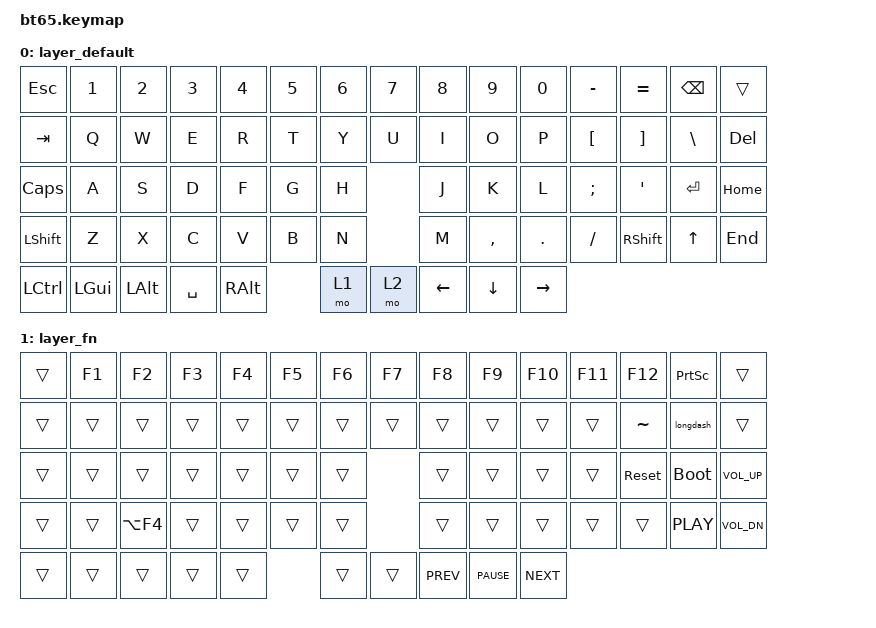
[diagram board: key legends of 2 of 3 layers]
#include <behaviors.dtsi>
#include <dt-bindings/zmk/keys.h>
#include <dt-bindings/zmk/bt.h>
#include <dt-bindings/zmk/rgb.h>
#include <dt-bindings/zmk/backlight.h>
#include <dt-bindings/zmk/ext_power.h>

/ {
    macros {
        longdash: longdash {
            label = "ZM_longdash";
            compatible = "zmk,behavior-macro";
            #binding-cells = <0>;
            bindings
                = <&macro_press &kp LALT>
                , <&macro_tap &kp KP_N0 &kp KP_N1 &kp KP_N5 &kp KP_N0>
                , <&macro_release &kp LALT>
                ;
        };
    };
};

/ {
	keymap {
		compatible = "zmk,keymap";

		layer_default {
			bindings = <

				&kp ESC &kp N1 &kp N2 &kp N3 &kp N4 &kp N5 &kp N6 &kp N7 &kp N8 &kp N9 &kp N0 &kp MINUS &kp EQUAL &kp BKSP &trans
				&kp TAB &kp Q &kp W &kp E &kp R &kp T &kp Y &kp U &kp I &kp O &kp P &kp LBKT &kp RBKT &kp BACKSLASH &kp DEL
				&kp CLCK &kp A &kp S &kp D &kp F &kp G &kp H &kp J &kp K &kp L &kp SEMI &kp SQT &kp RET &kp HOME
				&kp LSHFT &kp Z &kp X &kp C &kp V &kp B &kp N &kp M &kp COMMA &kp DOT &kp FSLH &kp RSHFT &kp UP &kp END
				&kp LCTRL &kp LGUI &kp LALT &kp SPACE &kp RALT &mo 1 &mo 2 &kp LEFT &kp DOWN &kp RIGHT
			>;
		};
		layer_fn {
			bindings = <
				&trans &kp F1 &kp F2 &kp F3 &kp F4 &kp F5 &kp F6 &kp F7 &kp F8 &kp F9 &kp F10 &kp F11 &kp F12 &kp PSCRN &trans
				&trans &trans &trans &trans &trans &trans &trans &trans &trans &trans &trans &trans &kp TILDE &longdash &trans
				&trans &trans &trans &trans &trans &trans &trans &trans &trans &trans &trans &sys_reset &bootloader &kp C_VOL_UP
				&trans &trans &kp LA(F4) &trans &trans &trans &trans &trans &trans &trans &trans &trans &kp C_PLAY &kp C_VOL_DN
				&trans &trans &trans &trans &trans &trans &trans &kp C_PREV &kp C_PAUSE &kp C_NEXT
			>;
		};
		layer_pn {
			bindings = <
				&trans &trans &trans &trans &trans &trans &trans &trans &trans &trans &trans &trans &trans &trans &trans
				&bt BT_CLR &trans &trans &trans &trans &trans &trans &trans &trans &trans &trans &trans &trans &trans &trans 
				&trans &trans &trans &trans &trans &trans &trans &trans &trans &trans &rgb_ug &trans &trans &bl BL_TOG &trans
				&trans &trans &trans &trans &trans &trans &trans &trans &trans &trans &trans &trans &bl BL_INC &trans
				&trans &trans &trans &trans &trans &trans &trans &trans &bl BL_DEC &trans
			>;
		};
	};
};
